# CW32L010 register map
Vendor: Wuhan Xinyuan Semiconductor Co.Ltd; Series: ARMCM0P; File version: 1.2
CW32L010x8xx
CPU: CM0+ r0p1, little endian, no MPU, no FPU, 2 interrupt priority bits
Registers are 32-bit, read-write, no defined reset value unless marked. A register's access mark holds for its fields unless they carry their own. Offsets are from the block's base; lines under a group give offsets from that group; [hi:lo] are bit positions; {n}, {i} and the like mark numbered series; 'fields as' and 'values as' point back to an identical list; <NAME> marks a mode.

## Memory map
0x40000000 ADC size 0x80
0x400000A0 VCDIV size 0x4
0x400000A4 VC1 size 0xC
0x400000B4 VC2 size 0xC
0x400000D0 LVD size 0xC
0x40000800 SPI size 0x20
0x40000C00 UART1 size 0x40
0x40001000 UART2 size 0x40
0x40001400 ATIM size 0x74
0x40001800 GTIM1 size 0x74 — General Timer 1
0x40004000 SYSCTRL size 0x74 — System Ctrl
0x40004080 IRMOD size 0xC
0x40004400 RTC size 0x5C
0x40004800 BTIM1 size 0x30 — Base Timer 1
0x40004840 BTIM2 size 0x30 — Base Timer 2
0x40004880 BTIM3 size 0x30 — Base Timer 3
0x40005000 IWDT size 0x28
0x40005800 I2C1 size 0x2C
0x40006000 LPTIM size 0x20
0x40022000 FLASH size 0x74
0x40022400 RAM size 0x10
0x40023000 CRC size 0x14
0x48000000 GPIOA size 0x64
0x48000100 GPIOB size 0x64

## Interrupts
0 WDT (IWDT) — Watch Dog Timer Interrupt
1 LVD — Low Voltage Detect Interrupt
2 RTC — Real Time Clock Interrupt
3 FLASHRAM (FLASH) — Flash/RAM Interrupt
4 SYSCTRL — SYSCTRL Interupt
5 GPIOA — GPIOA Interrupt
6 GPIOB — GPIOB Interrupt
12 ADC — ADC Interrupt
13 ATIM — Advanced Timer Interrupt
14 VC1 — Voltage Comparator 1 Interrupt
15 VC2 — Voltage Comparator 2 Interrupt
16 GTIM1 — General Timer1 Interrupt
19 LPTIM — LPTIM Interrupt
20 BTIM1 — Base Timer1 Interrupt
21 BTIM2 — Base Timer2 Interrupt
22 BTIM3 — Base Timer3 Interrupt
23 I2C1 — I2C1 Interrupt
25 SPI — SPI Interrupt
27 UART1 — UART1 Interrupt
28 UART2 — UART2 Interrupt
31 CLKFAULT (SYSCTRL) — Clock Fault Interupt

## ADC
Base 0x40000000
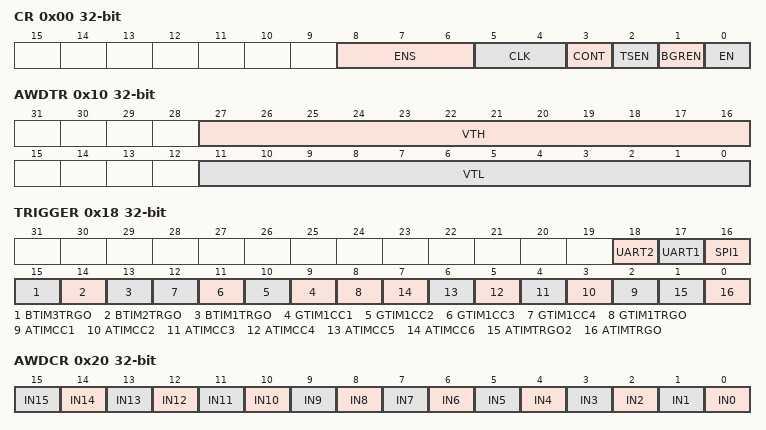
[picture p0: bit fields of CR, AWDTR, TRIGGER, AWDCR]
0x00 CR
  [8:6] ENS
  [5:4] CLK — desc CLKSRC
  [3] CONT
  [2] TSEN
  [1] BGREN
  [0] EN
0x08 START
  [0] START
0x10 AWDTR
  [27:16] VTH, [11:0] VTL
0x18 TRIGGER
  [18] UART2, [17] UART1, [16] SPI1, [15] BTIM3TRGO, [14] BTIM2TRGO, [13] BTIM1TRGO, [n+8] GTIM1CC{n} (n=1..4), [8] GTIM1TRGO, [n+1] ATIMCC{n} (n=1..6), [1] ATIMTRGO2, [0] ATIMTRGO
0x20 AWDCR
  [n] IN{n} (n=0..15)
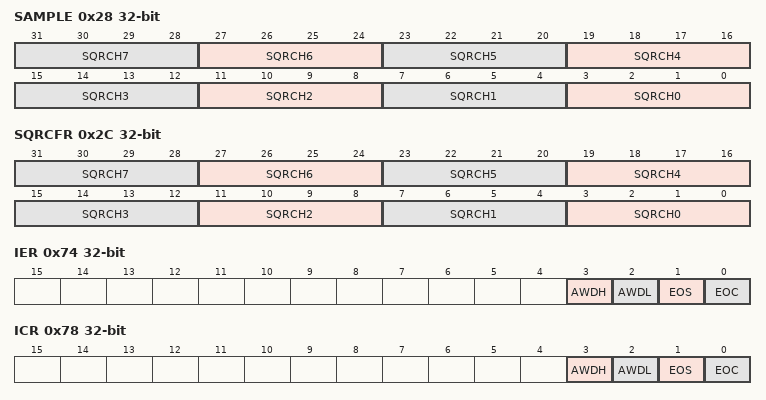
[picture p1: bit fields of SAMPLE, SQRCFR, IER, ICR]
0x28 SAMPLE
  [4n+3:4n] SQRCH{n} (n=0..7)
0x2C SQRCFR
  [4n+3:4n] SQRCH{n} (n=0..7)
{0x40+4i} RESULT{i} ro (i=0..7)
  [15:0] RESULT
0x74 IER
  [3] AWDH, [2] AWDL, [1] EOS, [0] EOC
0x78 ICR
  [3] AWDH, [2] AWDL, [1] EOS, [0] EOC
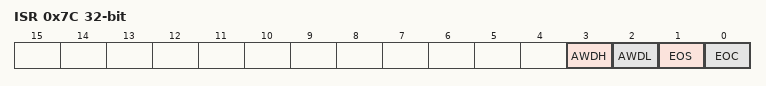
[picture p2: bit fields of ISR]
0x7C ISR ro
  [3] AWDH, [2] AWDL, [1] EOS, [0] EOC

## ATIM
Base 0x40001400
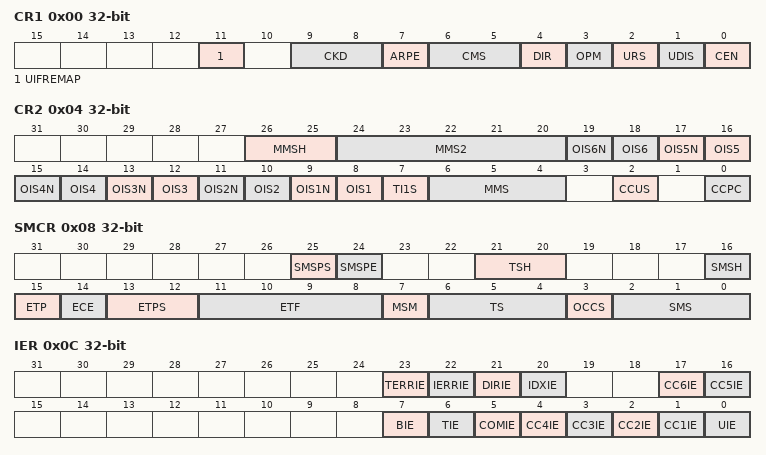
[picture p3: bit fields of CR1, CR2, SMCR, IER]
0x00 CR1 — Control Register1
  [11] UIFREMAP, [9:8] CKD, [7] ARPE, [6:5] CMS, [4] DIR, [3] OPM, [2] URS, [1] UDIS, [0] CEN
0x04 CR2 — Control Register2
  [26:25] MMSH, [24:20] MMS2, [2n+7] OIS{n}N (n=1..6), [2n+6] OIS{n} (n=1..6), [7] TI1S, [6:4] MMS, [2] CCUS, [0] CCPC
0x08 SMCR — Slave Mode Control Register
  [25] SMSPS, [24] SMSPE, [21:20] TSH, [16] SMSH, [15] ETP, [14] ECE, [13:12] ETPS, [11:8] ETF, [7] MSM, [6:4] TS, [3] OCCS, [2:0] SMS
0x0C IER — Interrupt Enable Register
  [23] TERRIE, [22] IERRIE, [21] DIRIE, [20] IDXIE, [17] CC6IE, [16] CC5IE, [7] BIE, [6] TIE, [5] COMIE, [n] CC{n}IE (n=1..4), [0] UIE
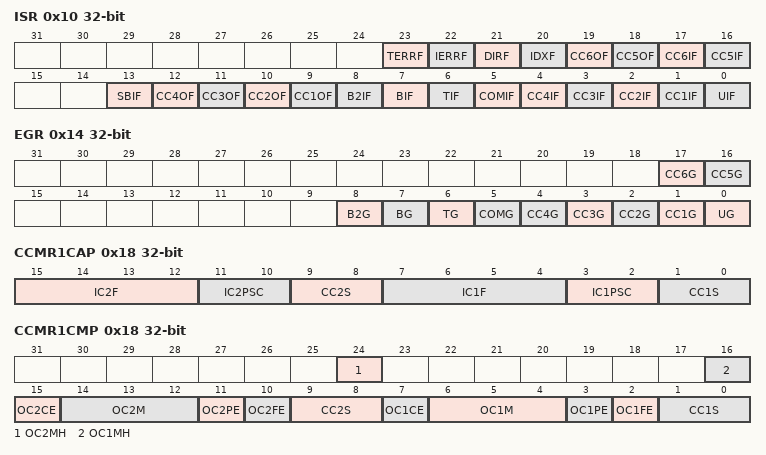
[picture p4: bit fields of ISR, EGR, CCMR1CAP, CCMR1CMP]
0x10 ISR ro — Interrupt status register
  [23] TERRF, [22] IERRF, [21] DIRF, [20] IDXF, [19] CC6OF, [18] CC5OF, [17] CC6IF, [16] CC5IF, [13] SBIF, [n+8] CC{n}OF (n=1..4), [8] B2IF, [7] BIF, [6] TIF, [5] COMIF, [n] CC{n}IF (n=1..4), [0] UIF
0x14 EGR — Event generation register
  [17] CC6G, [16] CC5G, [8] B2G, [7] BG, [6] TG, [5] COMG, [n] CC{n}G (n=1..4), [0] UG
0x18 CCMR1CAP — capture compare mode register 1
  [15:12] IC2F, [11:10] IC2PSC, [9:8] CC2S, [7:4] IC1F, [3:2] IC1PSC, [1:0] CC1S
0x18 CCMR1CMP (alternate view of CCMR1CAP) — capture compare mode register 1
  [24] OC2MH, [16] OC1MH, [15] OC2CE, [14:12] OC2M, [11] OC2PE, [10] OC2FE, [9:8] CC2S, [7] OC1CE, [6:4] OC1M, [3] OC1PE, [2] OC1FE, [1:0] CC1S
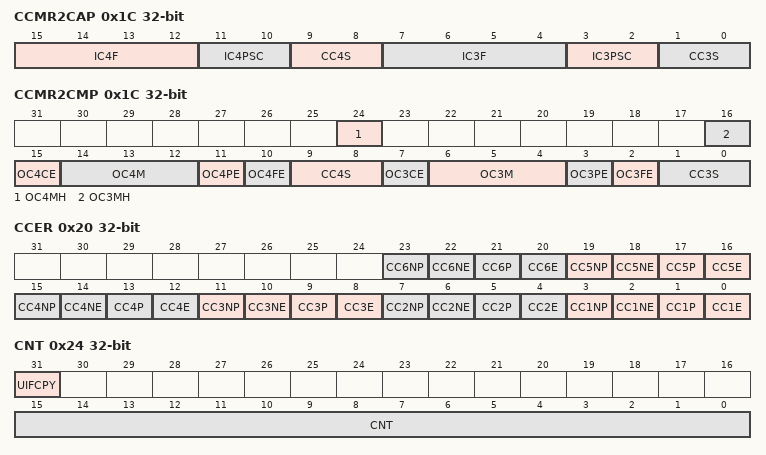
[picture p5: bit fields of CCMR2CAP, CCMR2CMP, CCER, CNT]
0x1C CCMR2CAP — capture compare mode register 2
  [15:12] IC4F, [11:10] IC4PSC, [9:8] CC4S, [7:4] IC3F, [3:2] IC3PSC, [1:0] CC3S
0x1C CCMR2CMP (alternate view of CCMR2CAP) — capture compare mode register 2
  [24] OC4MH, [16] OC3MH, [15] OC4CE, [14:12] OC4M, [11] OC4PE, [10] OC4FE, [9:8] CC4S, [7] OC3CE, [6:4] OC3M, [3] OC3PE, [2] OC3FE, [1:0] CC3S
0x20 CCER — capture compare enable register
  [4n-1] CC{n}NP (n=1..6), [4n-2] CC{n}NE (n=1..6), [4n-3] CC{n}P (n=1..6), [4n-4] CC{n}E (n=1..6)
0x24 CNT — Counter Register
  [31] UIFCPY ro, [15:0] CNT
0x28 PSC — prescaler Register
  [15:0] PSC
0x2C ARR — Auto reload Register
  [15:0] ARR
0x30 RCR — Repetition Counter Register
  [15:0] REP
{0x30+4i} CCR{i} (i=1..4) — capture compare register{i}
  [15:0] CCR{i}
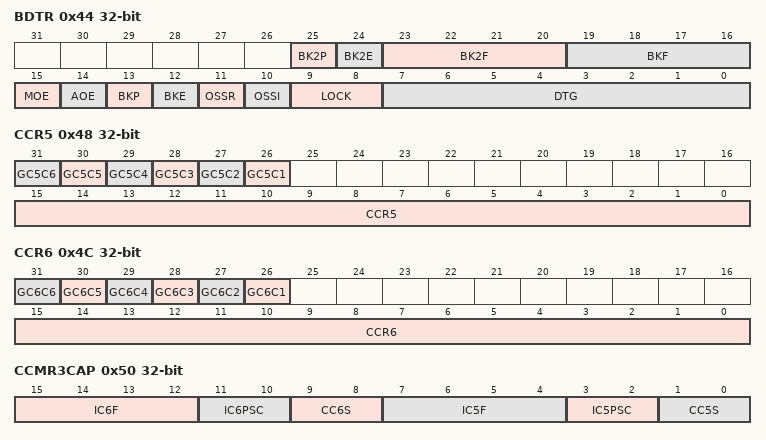
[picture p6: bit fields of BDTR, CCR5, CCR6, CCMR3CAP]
0x44 BDTR — break and dead-time register
  [25] BK2P, [24] BK2E, [23:20] BK2F, [19:16] BKF, [15] MOE, [14] AOE, [13] BKP, [12] BKE, [11] OSSR, [10] OSSI, [9:8] LOCK, [7:0] DTG
0x48 CCR5 — capture compare register5
  [n+25] GC5C{n} (n=1..6), [15:0] CCR5
0x4C CCR6 — capture compare register6
  [n+25] GC6C{n} (n=1..6), [15:0] CCR6
0x50 CCMR3CAP — capture compare mode register 3
  [15:12] IC6F, [11:10] IC6PSC, [9:8] CC6S, [7:4] IC5F, [3:2] IC5PSC, [1:0] CC5S
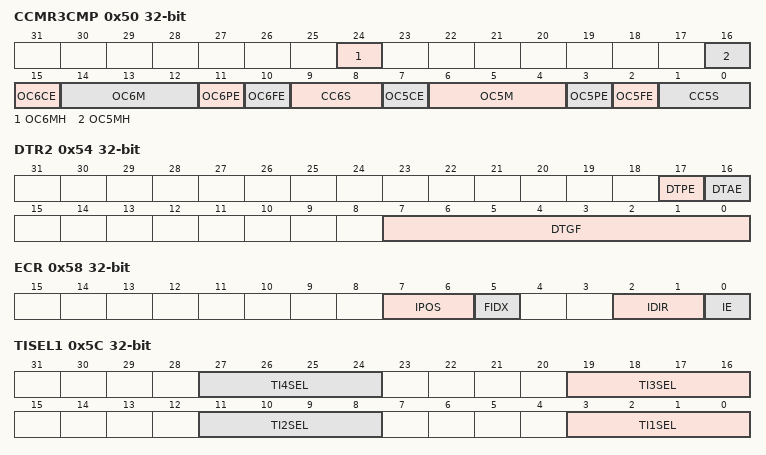
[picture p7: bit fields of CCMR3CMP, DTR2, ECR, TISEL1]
0x50 CCMR3CMP (alternate view of CCMR3CAP) — capture compare mode register 3
  [24] OC6MH, [16] OC5MH, [15] OC6CE, [14:12] OC6M, [11] OC6PE, [10] OC6FE, [9:8] CC6S, [7] OC5CE, [6:4] OC5M, [3] OC5PE, [2] OC5FE, [1:0] CC5S
0x54 DTR2 — dead-time register2
  [17] DTPE, [16] DTAE, [7:0] DTGF
0x58 ECR — Encoder control Register
  [7:6] IPOS, [5] FIDX, [2:1] IDIR, [0] IE
0x5C TISEL1 — Timer Input Select Register1
  [8n-5:8n-8] TI{n}SEL (n=1..4)
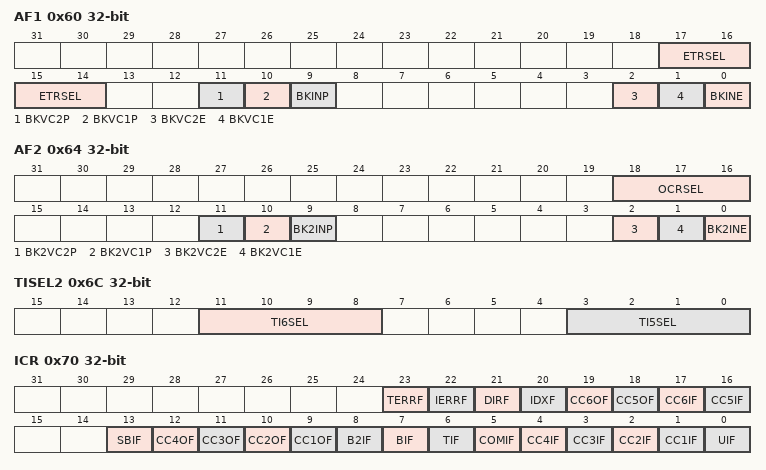
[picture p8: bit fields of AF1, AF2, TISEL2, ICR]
0x60 AF1 — Alternate function Register1
  [17:14] ETRSEL, [11] BKVC2P, [10] BKVC1P, [9] BKINP, [2] BKVC2E, [1] BKVC1E, [0] BKINE
0x64 AF2 — Alternate function Register2
  [18:16] OCRSEL, [11] BK2VC2P, [10] BK2VC1P, [9] BK2INP, [2] BK2VC2E, [1] BK2VC1E, [0] BK2INE
0x6C TISEL2 — Timer Input Select Register2
  [11:8] TI6SEL, [3:0] TI5SEL
0x70 ICR — Interrupt clean register
  fields as ISR
